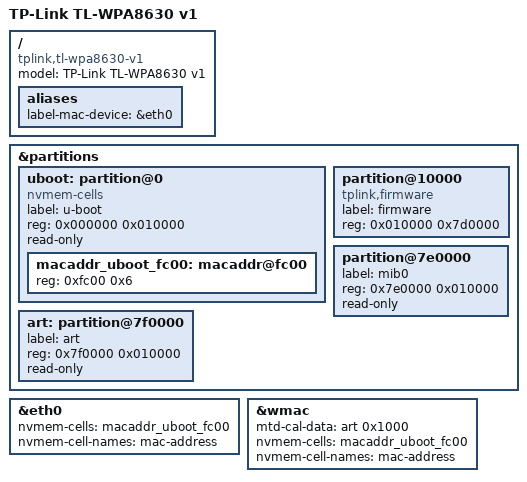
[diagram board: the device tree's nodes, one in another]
// SPDX-License-Identifier: GPL-2.0-or-later OR MIT

#include "qca9563_tplink_tl-wpa8630.dtsi"

/ {
	compatible = "tplink,tl-wpa8630-v1", "qca,qca9563";
	model = "TP-Link TL-WPA8630 v1";

	aliases {
		label-mac-device = &eth0;
	};
};

&partitions {
	uboot: partition@0 {
		label = "u-boot";
		reg = <0x000000 0x010000>;
		read-only;
	};

	partition@10000 {
		compatible = "tplink,firmware";
		label = "firmware";
		reg = <0x010000 0x7d0000>;
	};

	partition@7e0000 {
		label = "mib0";
		reg = <0x7e0000 0x010000>;
		read-only;
	};

	art: partition@7f0000 {
		label = "art";
		reg = <0x7f0000 0x010000>;
		read-only;
	};
};

&eth0 {
	nvmem-cells = <&macaddr_uboot_fc00>;
	nvmem-cell-names = "mac-address";
};

&wmac {
	mtd-cal-data = <&art 0x1000>;

	nvmem-cells = <&macaddr_uboot_fc00>;
	nvmem-cell-names = "mac-address";
};

&uboot {
	compatible = "nvmem-cells";
	#address-cells = <1>;
	#size-cells = <1>;

	macaddr_uboot_fc00: macaddr@fc00 {
		reg = <0xfc00 0x6>;
	};
};
